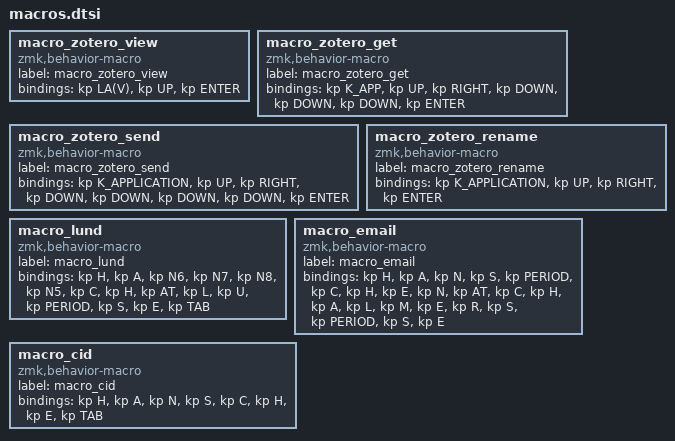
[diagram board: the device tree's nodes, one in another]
macro_zotero_view: macro_zotero_view{
compatible = "zmk,behavior-macro";
label = "macro_zotero_view";
#binding-cells = <0>;
bindings = <&kp LA(V)>, <&kp UP>, <&kp ENTER>;
};
macro_zotero_get: macro_zotero_get{
compatible = "zmk,behavior-macro";
label = "macro_zotero_get";
#binding-cells = <0>;
bindings = <&kp K_APP>, <&kp UP>, <&kp RIGHT>, <&kp DOWN>, <&kp DOWN>, <&kp DOWN>, <&kp ENTER>;
};
macro_zotero_send: macro_zotero_send{
compatible = "zmk,behavior-macro";
label = "macro_zotero_send";
#binding-cells = <0>;
bindings = <&kp K_APPLICATION>, <&kp UP>, <&kp RIGHT>, <&kp DOWN>, <&kp DOWN>, <&kp DOWN>, <&kp DOWN>, <&kp ENTER>;
};
macro_zotero_rename: macro_zotero_rename{
compatible = "zmk,behavior-macro";
label = "macro_zotero_rename";
#binding-cells = <0>;
bindings = <&kp K_APPLICATION>, <&kp UP>, <&kp RIGHT>, <&kp ENTER>;
};
macro_lund: macro_lund{
compatible = "zmk,behavior-macro";
label = "macro_lund";
#binding-cells = <0>;
bindings = <&kp H>, <&kp A>, <&kp N6>, <&kp N7>, <&kp N8>, <&kp N5>, <&kp C>, <&kp H>, <&kp AT>, <&kp L>, <&kp U>, <&kp PERIOD>, <&kp S>, <&kp E>, <&kp TAB>;
};
macro_email: macro_email{
compatible = "zmk,behavior-macro";
label = "macro_email";
#binding-cells = <0>;
bindings = <&kp H>, <&kp A>, <&kp N>, <&kp S>, <&kp PERIOD>, <&kp C>, <&kp H>, <&kp E>, <&kp N>, <&kp AT>, <&kp C>, <&kp H>, <&kp A>, <&kp L>, <&kp M>, <&kp E>, <&kp R>, <&kp S>, <&kp PERIOD>, <&kp S>, <&kp E>;
};
macro_cid: macro_cid{
compatible = "zmk,behavior-macro";
label = "macro_cid";
#binding-cells = <0>;
bindings = <&kp H>, <&kp A>, <&kp N>, <&kp S>, <&kp C>, <&kp H>, <&kp E>, <&kp TAB>;
};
